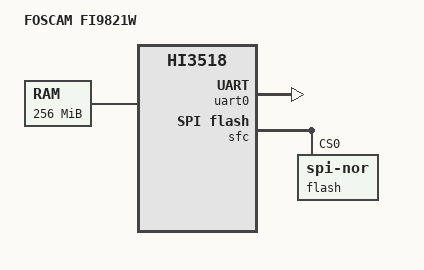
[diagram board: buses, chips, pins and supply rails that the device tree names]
// SPDX-License-Identifier: GPL-2.0-or-later
// Copyright (c) 2023 Jonathan Neuschäfer
//
// FOSCAM FI9821W IP Camera, based on the Hi3518A V100 SoC

/dts-v1/;
#include "hi3518a.dtsi"

/ {
	model = "FOSCAM FI9821W";
	compatible = "foscam,fi9821w", "hisilicon,hi3518";

	memory@80000000 {
		device_type = "memory";
		reg = <0x80000000 0x10000000>;
	};

	chosen {
		stdout-path = "serial0:115200n8";
	};
};

&uart0 {
	status = "okay";
};

&sfc {
	status = "okay";

	flash@0 {
		reg = <0>;
		compatible = "jedec,spi-nor";
	};
};
